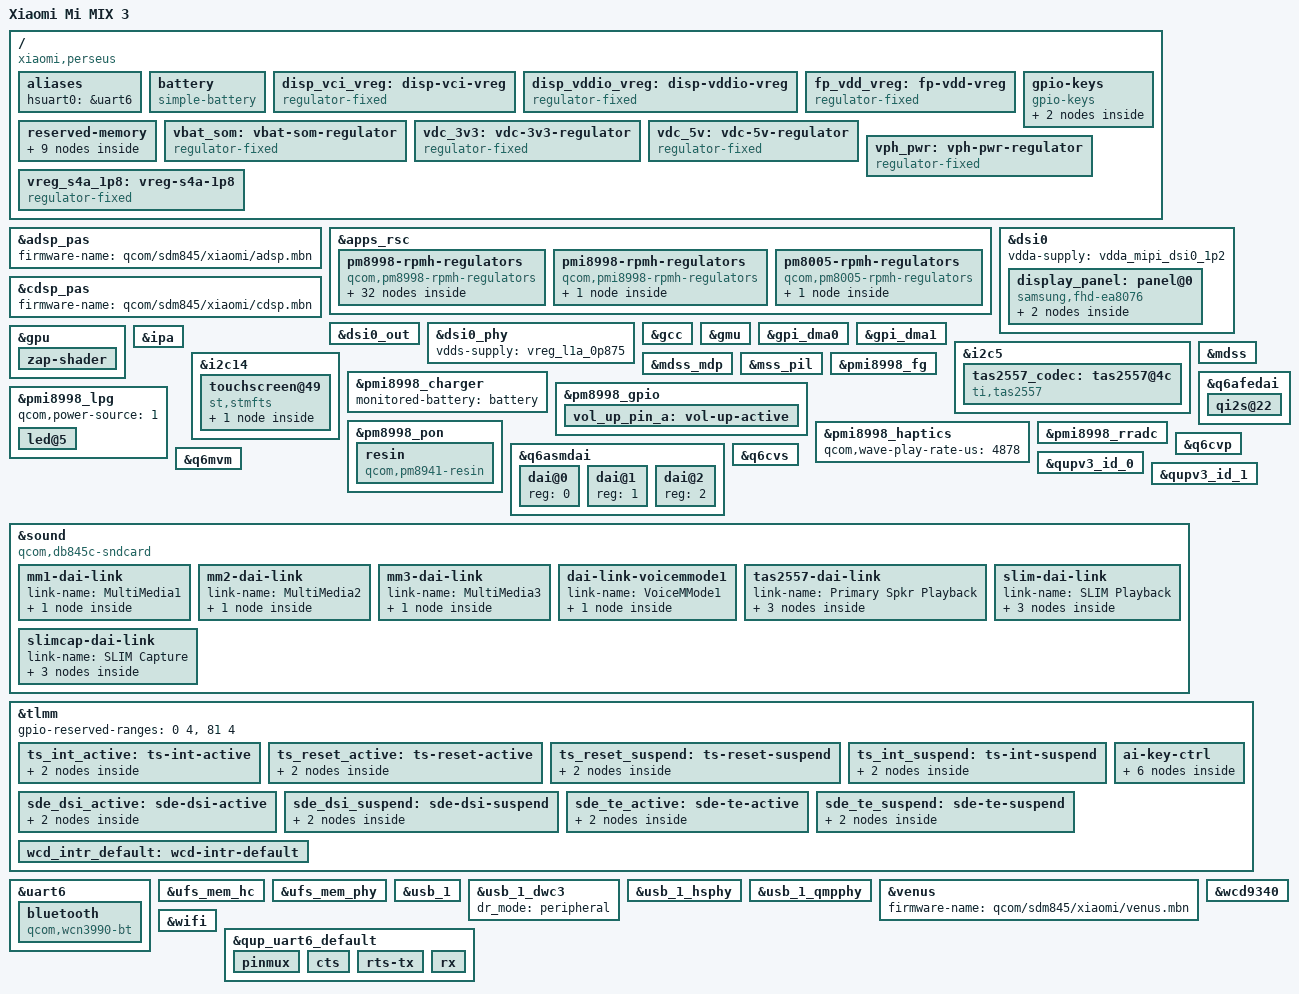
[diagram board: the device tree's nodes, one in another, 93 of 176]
// SPDX-License-Identifier: GPL-2.0
/*
 * Copyright (c) 2021, BigfootACA <bigfoot@classfun.cn>
 * Copyright (c) 2022, Pysen X <pysen@svartavillan.se>
 */

/dts-v1/;

#include <dt-bindings/gpio/gpio.h>
#include <dt-bindings/pinctrl/qcom,pmic-gpio.h>
#include <dt-bindings/regulator/qcom,rpmh-regulator.h>
#include <dt-bindings/sound/qcom,q6afe.h>
#include <dt-bindings/sound/qcom,q6asm.h>
#include <dt-bindings/sound/qcom,q6afe.h>
#include <dt-bindings/sound/qcom,q6asm.h>
#include <dt-bindings/sound/qcom,q6voice.h>
#include "sdm845.dtsi"
#include "pm8998.dtsi"
#include "pmi8998.dtsi"
#include "pm8005.dtsi"

/*
 * Delete following upstream (sdm845.dtsi) reserved
 * memory mappings which are different in this device.
 */
/delete-node/ &rmtfs_mem;
/delete-node/ &adsp_mem;
/delete-node/ &wlan_msa_mem;
/delete-node/ &mpss_region;
/delete-node/ &venus_mem;
/delete-node/ &cdsp_mem;
/delete-node/ &mba_region;
/delete-node/ &slpi_mem;
/delete-node/ &spss_mem;

/ {
	model = "Xiaomi Mi MIX 3";
	compatible = "xiaomi,perseus", "qcom,sdm845";

	/* required for bootloader to select correct board */
	qcom,board-id = <0x63 0x0>;
	qcom,msm-id = <0x141 0x20001>;
	aliases {
		hsuart0 = &uart6;	
	};

	battery: battery {
		compatible = "simple-battery";

		charge-full-design-microamp-hours = <3200000>;
		voltage-min-design-microvolt = <3700000>;
		voltage-max-design-microvolt = <4400000>;
	};

	disp_vci_vreg: disp-vci-vreg {
		compatible = "regulator-fixed";
		regulator-name = "disp_vci_vreg";
		start-delay-us = <4000>;
		regulator-always-on;
		regulator-boot-on;
		enable-active-high;
		gpio = <&tlmm 99 0>;
	};

	disp_vddio_vreg: disp-vddio-vreg {
		compatible = "regulator-fixed";
		regulator-name = "disp_vddio_vreg";
		startup-delay-us = <4000>;
		regulator-always-on;
		regulator-boot-on;
		enable-active-high;
		gpio = <&tlmm 79 0>;
	};

	fp_vdd_vreg: fp-vdd-vreg {
		compatible = "regulator-fixed";
		regulator-name = "fp_vdd_vreg";
		startup-delay-us = <4000>;
		regulator-always-on;
		enable-active-high;
		gpio = <&tlmm 50 0>;
	};

	gpio-keys {
		compatible = "gpio-keys";
		autorepeat;

		pinctrl-names = "default";
		pinctrl-0 = <&vol_up_pin_a &ai_key_active_default>;

		vol-up {
			label = "Volume Up";
			linux,code = <KEY_VOLUMEUP>;
			gpios = <&pm8998_gpio 6 GPIO_ACTIVE_LOW>;
		};

		ai-key {
			label = "AI Key";
			linux,code = <KEY_ASSISTANT>;
			gpios = <&tlmm 44 GPIO_ACTIVE_LOW>;
			// debounce-interval = <39>;
		};
	};

	/* Reserved memory changes from downstream */
	reserved-memory {
		adsp_mem: memory@8c500000 {
			reg = <0 0x8c500000 0 0x1e00000>;
			no-map;
		};

		wlan_msa_mem: memory@8e300000 {
			reg = <0 0x8e300000 0 0x100000>;
			no-map;
		};

		mpss_region: memory@8e400000 {
			reg = <0 0x8e400000 0 0x7800000>;
			no-map;
		};

		venus_mem: memory@95c00000 {
			reg = <0 0x95c00000 0 0x500000>;
			no-map;
		};

		cdsp_mem: memory@96100000 {
			reg = <0 0x96100000 0 0x800000>;
			no-map;
		};

		mba_region: memory@96900000 {
			reg = <0 0x96900000 0 0x200000>;
			no-map;
		};

		slpi_mem: memory@96b00000 {
			reg = <0 0x96b00000 0 0x1400000>;
			no-map;
		};

		spss_mem: memory@97f00000 {
			reg = <0 0x97f00000 0 0x100000>;
			no-map;
		};

		rmtfs_mem: memory@f6301000 {
			compatible = "qcom,rmtfs-mem";
			reg = <0 0xf6301000 0 0x200000>;
			no-map;

			qcom,client-id = <1>;
			qcom,vmid = <15>;
		};
	};

	vbat_som: vbat-som-regulator {
		compatible = "regulator-fixed";
		regulator-name = "VBAT_SOM";
		vin-supply = <&vph_pwr>;
		regulator-min-microvolt = <4200000>;
		regulator-max-microvolt = <4200000>;
		regulator-always-on;
	};

	vdc_3v3: vdc-3v3-regulator {
		compatible = "regulator-fixed";
		regulator-name = "VDC_3V3";
		vin-supply = <&vph_pwr>;
		regulator-min-microvolt = <3300000>;
		regulator-max-microvolt = <3300000>;
		regulator-always-on;
	};

	vdc_5v: vdc-5v-regulator {
		compatible = "regulator-fixed";
		regulator-name = "VDC_5V";
		vin-supply = <&vph_pwr>;
		regulator-min-microvolt = <500000>;
		regulator-max-microvolt = <500000>;
		regulator-always-on;
	};

	vph_pwr: vph-pwr-regulator {
		compatible = "regulator-fixed";
		regulator-name = "vph_pwr";
		regulator-min-microvolt = <3700000>;
		regulator-max-microvolt = <3700000>;
	};

	vreg_s4a_1p8: vreg-s4a-1p8 {
		compatible = "regulator-fixed";
		regulator-name = "vreg_s4a_1p8";

		regulator-min-microvolt = <1800000>;
		regulator-max-microvolt = <1800000>;
		regulator-always-on;
		regulator-boot-on;
		vin-supply = <&vph_pwr>;
	};
};

&adsp_pas {
	status = "okay";
	firmware-name = "qcom/sdm845/xiaomi/adsp.mbn";
};

&apps_rsc {
	pm8998-rpmh-regulators {
		compatible = "qcom,pm8998-rpmh-regulators";
		qcom,pmic-id = "a";
		vdd-s1-supply = <&vph_pwr>;
		vdd-s2-supply = <&vph_pwr>;
		vdd-s3-supply = <&vph_pwr>;
		vdd-s4-supply = <&vph_pwr>;
		vdd-s5-supply = <&vph_pwr>;
		vdd-s6-supply = <&vph_pwr>;
		vdd-s7-supply = <&vph_pwr>;
		vdd-s8-supply = <&vph_pwr>;
		vdd-s9-supply = <&vph_pwr>;
		vdd-s10-supply = <&vph_pwr>;
		vdd-s11-supply = <&vph_pwr>;
		vdd-s12-supply = <&vph_pwr>;
		vdd-s13-supply = <&vph_pwr>;
		vdd-l1-l27-supply = <&vreg_s7a_1p025>;
		vdd-l2-l8-l17-supply = <&vreg_s3a_1p35>;
		vdd-l3-l11-supply = <&vreg_s7a_1p025>;
		vdd-l4-l5-supply = <&vreg_s7a_1p025>;
		vdd-l6-supply = <&vph_pwr>;
		vdd-l7-l12-l14-l15-supply = <&vreg_s5a_2p04>;
		vdd-l9-supply = <&vreg_bob>;
		vdd-l10-l23-l25-supply = <&vreg_bob>;
		vdd-l13-l19-l21-supply = <&vreg_bob>;
		vdd-l16-l28-supply = <&vreg_bob>;
		vdd-l18-l22-supply = <&vreg_bob>;
		vdd-l20-l24-supply = <&vreg_bob>;
		vdd-l26-supply = <&vreg_s3a_1p35>;
		vin-lvs-1-2-supply = <&vreg_s4a_1p8>;

		vreg_s2a_1p1: smps2 {
			regulator-always-on;
			regulator-min-microvolt = <1100000>;
			regulator-max-microvolt = <1100000>;
		};

		vreg_s3a_1p35: smps3 {
			regulator-min-microvolt = <1352000>;
			regulator-max-microvolt = <1352000>;
		};

		vreg_s5a_2p04: smps5 {
			regulator-always-on;
			regulator-min-microvolt = <1904000>;
			regulator-max-microvolt = <2040000>;
		};

		vreg_s7a_1p025: smps7 {
			regulator-always-on;
			regulator-min-microvolt = <900000>;
			regulator-max-microvolt = <1028000>;
		};

		vdda_ufs1_core:
		vreg_l1a_0p875: ldo1 {
			regulator-min-microvolt = <880000>;
			regulator-max-microvolt = <880000>;
			regulator-initial-mode = <RPMH_REGULATOR_MODE_HPM>;
		};

		vreg_l2a_0p875: ldo2 {
			regulator-min-microvolt = <1200000>;
			regulator-max-microvolt = <1200000>;
			regulator-initial-mode = <RPMH_REGULATOR_MODE_HPM>;
			regulator-always-on;
		};

		reg_l3a_0p875: ldo3 {
			regulator-min-microvolt = <1000000>;
			regulator-max-microvolt = <1000000>;
			regulator-initial-mode = <RPMH_REGULATOR_MODE_HPM>;
		};

		vreg_l5a_0p8: ldo5 {
			regulator-min-microvolt = <800000>;
			regulator-max-microvolt = <800000>;
			regulator-initial-mode = <RPMH_REGULATOR_MODE_HPM>;
		};

		vreg_l6a_1p8: ldo6 {
			regulator-min-microvolt = <1856000>;
			regulator-max-microvolt = <1856000>;
			regulator-initial-mode = <RPMH_REGULATOR_MODE_HPM>;
		};

		vreg_l7a_1p8: ldo7 {
			regulator-min-microvolt = <1800000>;
			regulator-max-microvolt = <1800000>;
			regulator-initial-mode = <RPMH_REGULATOR_MODE_HPM>;
		};

		vreg_l8a_1p2: ldo8 {
			regulator-min-microvolt = <1200000>;
			regulator-max-microvolt = <1248000>;
			regulator-initial-mode = <RPMH_REGULATOR_MODE_HPM>;
		};

		vreg_l9a_2p95: ldo9 {
			regulator-min-microvolt = <1704000>;
			regulator-max-microvolt = <2928000>;
			regulator-initial-mode = <RPMH_REGULATOR_MODE_HPM>;
		};

		vreg_l10a_2p95: ldo10 {
			regulator-min-microvolt = <1704000>;
			regulator-max-microvolt = <2928000>;
			regulator-initial-mode = <RPMH_REGULATOR_MODE_HPM>;
		};

		vreg_l11a_1p05: ldo11 {
			regulator-min-microvolt = <1000000>;
			regulator-max-microvolt = <1048000>;
			regulator-initial-mode = <RPMH_REGULATOR_MODE_HPM>;
		};

		vreg_l12a_1p8: ldo12 {
			regulator-min-microvolt = <1800000>;
			regulator-max-microvolt = <1800000>;
			regulator-initial-mode = <RPMH_REGULATOR_MODE_HPM>;
		};

		vreg_l13a_2p95: ldo13 {
			regulator-min-microvolt = <1800000>;
			regulator-max-microvolt = <2960000>;
			regulator-initial-mode = <RPMH_REGULATOR_MODE_HPM>;
		};

		vreg_l14a_1p8: ldo14 {
			regulator-min-microvolt = <1800000>;
			regulator-max-microvolt = <1800000>;
			regulator-always-on;
			regulator-boot-on;
			regulator-initial-mode = <RPMH_REGULATOR_MODE_HPM>;
		};

		vreg_l15a_1p8: ldo15 {
			regulator-min-microvolt = <1800000>;
			regulator-max-microvolt = <1800000>;
			regulator-initial-mode = <RPMH_REGULATOR_MODE_HPM>;
		};

		vreg_l16a_2p7: ldo16 {
			regulator-min-microvolt = <2704000>;
			regulator-max-microvolt = <2704000>;
			regulator-initial-mode = <RPMH_REGULATOR_MODE_HPM>;
		};

		vreg_l17a_1p3: ldo17 {
			regulator-always-on;
			regulator-min-microvolt = <1304000>;
			regulator-max-microvolt = <1304000>;
			regulator-initial-mode = <RPMH_REGULATOR_MODE_HPM>;
		};

		vreg_l18a_2p9: ldo18 {
			regulator-min-microvolt = <2704000>;
			regulator-max-microvolt = <2960000>;
			regulator-initial-mode = <RPMH_REGULATOR_MODE_HPM>;
		};

		vreg_l19a_3p1: ldo19 {
			regulator-min-microvolt = <2856000>;
			regulator-max-microvolt = <3104000>;
			regulator-initial-mode = <RPMH_REGULATOR_MODE_HPM>;
		};

		vreg_l20a_2p95: ldo20 {
			regulator-min-microvolt = <2704000>;
			regulator-max-microvolt = <2960000>;
			regulator-initial-mode = <RPMH_REGULATOR_MODE_HPM>;
		};

		vreg_l21a_2p95: ldo21 {
			regulator-min-microvolt = <2704000>;
			regulator-max-microvolt = <2960000>;
			regulator-initial-mode = <RPMH_REGULATOR_MODE_HPM>;
		};

		vreg_l22a_3p3: ldo22 {
			regulator-min-microvolt = <2864000>;
			regulator-max-microvolt = <3312000>;
			regulator-initial-mode = <RPMH_REGULATOR_MODE_HPM>;
		};

		vreg_l23a_3p3: ldo23 {
			regulator-min-microvolt = <3000000>;
			regulator-max-microvolt = <3312000>;
			regulator-initial-mode = <RPMH_REGULATOR_MODE_HPM>;
		};

		vreg_l24a_3p075: ldo24 {
			regulator-min-microvolt = <3088000>;
			regulator-max-microvolt = <3088000>;
			regulator-initial-mode = <RPMH_REGULATOR_MODE_HPM>;
		};

		vreg_l25a_3p3: ldo25 {
			regulator-always-on;
			regulator-min-microvolt = <3000000>;
			regulator-max-microvolt = <3312000>;
			regulator-initial-mode = <RPMH_REGULATOR_MODE_HPM>;
		};

		vdda_mipi_dsi0_1p2:
		vdda_ufs1_1p2:
		vreg_l26a_1p2: ldo26 {
			regulator-min-microvolt = <1200000>;
			regulator-max-microvolt = <1200000>;
			regulator-initial-mode = <RPMH_REGULATOR_MODE_HPM>;
			regulator-boot-on;
		};

		vreg_l28a_3p0: ldo28 {
			regulator-min-microvolt = <2856000>;
			regulator-max-microvolt = <3008000>;
			regulator-initial-mode = <RPMH_REGULATOR_MODE_HPM>;
			regulator-always-on;
		};

		vreg_lvs1a_1p8: lvs1 {
			regulator-min-microvolt = <1800000>;
			regulator-max-microvolt = <1800000>;
			regulator-always-on;
		};

		vreg_lvs2a_1p8: lvs2 {
			regulator-min-microvolt = <1800000>;
			regulator-max-microvolt = <1800000>;
			regulator-always-on;
		};
	};

	pmi8998-rpmh-regulators {
		compatible = "qcom,pmi8998-rpmh-regulators";
		qcom,pmic-id = "b";
		vdd-bob-supply = <&vph_pwr>;
		vreg_bob: bob {
			regulator-min-microvolt = <3312000>;
			regulator-max-microvolt = <3600000>;
			regulator-initial-mode = <RPMH_REGULATOR_MODE_AUTO>;
			regulator-allow-bypass;
		};
	};

	pm8005-rpmh-regulators {
		compatible = "qcom,pm8005-rpmh-regulators";
		qcom,pmic-id = "c";
		vdd-s1-supply = <&vph_pwr>;
		vdd-s2-supply = <&vph_pwr>;
		vdd-s3-supply = <&vph_pwr>;
		vdd-s4-supply = <&vph_pwr>;
		vreg_smp3c_0p6: smps3 {
			regulator-min-microvolt = <600000>;
			regulator-max-microvolt = <600000>;
			regulator-always-on;
		};
	};
};

&cdsp_pas {
	status = "okay";
	firmware-name = "qcom/sdm845/xiaomi/cdsp.mbn";
};

&dsi0 {
	status = "okay";
	vdda-supply = <&vdda_mipi_dsi0_1p2>;

	#address-cells = <1>;
	#size-cells = <0>;

	display_panel: panel@0 {
		compatible = "samsung,fhd-ea8076";
		#address-cells = <1>;
		#size-cells = <0>;
		reg = <0>;
		vddio-supply = <&vreg_l14a_1p8>;
		reset-gpios = <&tlmm 6 GPIO_ACTIVE_LOW>;
		pinctrl-names = "default";
		pinctrl-0 = <&sde_dsi_active &sde_te_active>;
		port {
			panel_in: endpoint {
				remote-endpoint = <&dsi0_out>;
			};
		};
	};
};

&dsi0_out {
	remote-endpoint = <&panel_in>;
	data-lanes = <0 1 2 3>;
};

&dsi0_phy {
	status = "okay";
	vdds-supply = <&vreg_l1a_0p875>;
};

&gcc {
	protected-clocks = <GCC_QSPI_CORE_CLK>,
			   <GCC_QSPI_CORE_CLK_SRC>,
			   <GCC_QSPI_CNOC_PERIPH_AHB_CLK>,
			   <GCC_LPASS_Q6_AXI_CLK>,
			   <GCC_LPASS_SWAY_CLK>;
};

&gmu {
	status = "okay";
};

&gpi_dma0 {
	status = "okay";
};

&gpi_dma1 {
	status = "okay";
};

&gpu {
	status = "okay";

	zap-shader {
		memory-region = <&gpu_mem>;
		firmware-name = "qcom/sdm845/xiaomi/a630_zap.mbn";
	};
};

&ipa {
	status = "okay";
	memory-region = <&ipa_fw_mem>;
	firmware-name = "qcom/sdm845/xiaomi/ipa_fws.mbn";
};

&i2c5 {
	#dma-cells = <3>;
	status = "okay";

	clock-frequency = <400000>;
	dmas = <&gpi_dma0 0 5 QCOM_GPI_I2C>,
		   <&gpi_dma0 1 5 QCOM_GPI_I2C>;
	dma-names = "tx", "rx";

	tas2557_codec: tas2557@4c{
		#sound-dai-cells = <1>;
		compatible = "ti,tas2557";
		reg = <0x4c>;
		ti,cdc-reset-gpio = <&tlmm 69 0>;
		ti,irq-gpio = <&tlmm 30 0>;
		ti,i2s-bits = <16>;
		ti,bypass-tmax = <0>;
	};
};

&i2c14 {
	#dma-cells = <3>;
	status = "okay";

	clock-frequency = <400000>;

	dmas =  <&gpi_dma1 0 6 QCOM_GPI_I2C>,
		   <&gpi_dma1 1 6 QCOM_GPI_I2C>;
	dma-names = "tx", "rx";

	touchscreen@49 {
		compatible = "st,stmfts";
		reg = <0x49>;
		interrupt-parent = <&tlmm>;
		interrupts = <31 0x2008>;
		pinctrl-names = "pmx_ts_active", "pmx_ts_suspend";
		pinctrl-0 = <&ts_int_active &ts_reset_active>;
		pinctrl-1 = <&ts_int_suspend &ts_reset_suspend>;
		vdd-supply = <&disp_vddio_vreg>;
		avdd-supply = <&vreg_l28a_3p0>;
		fts,pwr-reg-name = "avdd";
		fts,bus-reg-name = "vdd";
		fts,irq-gpio = <&tlmm 31 0x2008>;
		fts,irq-gpio-name = "fts_irq";
		fts,reset-gpio-enable;
		fts,reset-gpio = <&tlmm 32 0x00>;
		fts,x-max = <1079>;
		fts,y-max = <2339>;
		fts,reset-gpio-name = "fts_rst";
		fts,irq-flags = <0x2008>;
		fts,key-num = <2>;
		fts,key-codes = <158 139>;
		fts,config-array-size = <1>;
		fts,default-fw-name = "st_fts_e5.ftb";
		fts,cfg_0 {
			fts,tp-vendor = <0x52>;
			fts,fw-name = "st_fts_e5.ftb";
			fts,limit-name = "stm_fts_production_limits.csv";
		};
	};
};

&mdss {
	status = "okay";
};

&mdss_mdp {
	status = "okay";
};

&mss_pil {
	status = "okay";
	firmware-name = "qcom/sdm845/xiaomi/mba.mbn", "qcom/sdm845/xiaomi/modem.mbn";
};

&pmi8998_charger {
	status = "okay";
	monitored-battery = <&battery>;
};

&pmi8998_fg {
	status = "okay";

	power-supplies = <&pmi8998_charger>;
	monitored-battery = <&battery>;
};

&pm8998_gpio {
	vol_up_pin_a: vol-up-active {
		pins = "gpio6";
		function = "normal";
		input-enable;
		bias-pull-up;
		qcom,drive-strength = <PMIC_GPIO_STRENGTH_NO>;
	};
};

&pmi8998_haptics {
	status = "okay";
	qcom,wave-play-rate-us = <4878>;
};

&pmi8998_lpg {
	status = "okay";
	qcom,power-source = <1>;
	led@5 {
		reg = <5>;
		label = "white";
	};
};

&pm8998_pon {
	resin {
		compatible = "qcom,pm8941-resin";
		interrupts = <0x0 0x8 1 IRQ_TYPE_EDGE_BOTH>;
		debounce = <15625>;
		bias-pull-up;
		linux,code = <KEY_VOLUMEDOWN>;
	};
};

&pmi8998_rradc {
	status = "okay";
};

&q6afedai {
	qi2s@22 {
		reg = <22>;
		qcom,sd-lines = <0 1 2 3>;
	};
};

&q6asmdai {
	dai@0 {
		reg = <0>;
	};

	dai@1 {
		reg = <1>;
	};

	dai@2 {
		reg = <2>;
	};
};

&q6cvp {
	status = "okay";
};

&q6cvs {
	status = "okay";
};

&q6mvm {
	status = "okay";
};

&qupv3_id_0 {
	status = "okay";
};

&qupv3_id_1 {
	status = "okay";
};

&sound {
	compatible = "qcom,db845c-sndcard";
	pinctrl-0 = <&quat_mi2s_active &quat_mi2s_sd0_active>;
	pinctrl-names = "default";
	model = "Xiaomi Mi MIX 3";
	audio-routing =
		"RX_BIAS", "MCLK",
		"AMIC1", "MIC BIAS1",
		"AMIC2", "MIC BIAS2",
		"AMIC3", "MIC BIAS3";

	mm1-dai-link {
		link-name = "MultiMedia1";
		cpu {
			sound-dai = <&q6asmdai MSM_FRONTEND_DAI_MULTIMEDIA1>;
		};
	};

	mm2-dai-link {
		link-name = "MultiMedia2";
		cpu {
			sound-dai = <&q6asmdai MSM_FRONTEND_DAI_MULTIMEDIA2>;
		};
	};

	mm3-dai-link {
		link-name = "MultiMedia3";
		cpu {
			sound-dai = <&q6asmdai MSM_FRONTEND_DAI_MULTIMEDIA3>;
		};
	};

	dai-link-voicemmode1 {
		link-name = "VoiceMMode1";
		cpu {
			sound-dai = <&q6voicedai VOICEMMODE1>;
		};
	};

	tas2557-dai-link {
		link-name = "Primary Spkr Playback";
		cpu {
			sound-dai = <&q6afedai QUATERNARY_MI2S_RX>;
		};

		platform {
			sound-dai = <&q6routing>;
		};

		codec {
			sound-dai = <&tas2557_codec 0>;
		};
	};

	slim-dai-link {
		link-name = "SLIM Playback";
		cpu {
			sound-dai = <&q6afedai SLIMBUS_0_RX>;
		};

		platform {
			sound-dai = <&q6routing>;
		};

		codec {
			sound-dai = <&wcd9340 0>;
		};
	};

	slimcap-dai-link {
		link-name = "SLIM Capture";
		cpu {
			sound-dai = <&q6afedai SLIMBUS_0_TX>;
		};

		platform {
			sound-dai = <&q6routing>;
		};

		codec {
			sound-dai = <&wcd9340 1>;
		};
	};
};

&tlmm {
	gpio-reserved-ranges = <0 4>, <81 4>;

	ts_int_active: ts-int-active {
		mux {
			pins = "gpio31";
			function = "gpio";
		};

		config {
			pins = "gpio31";
			drive-strength = <16>;
			bias-pull-down;
			input-enable;
		};
	};

	ts_reset_active: ts-reset-active {
		mux {
			pins = "gpio32";
			function = "gpio";
		};

		config {
			pins = "gpio32";
			drive-strength = <16>;
			output-high;
		};
	};

	ts_reset_suspend: ts-reset-suspend {
		mux {
			pins = "gpio32";
			function = "gpio";
		};

		config {
			pins = "gpio32";
			drive-strength = <2>;
			bias-disable;
			output-low;
		};
	};

	ts_int_suspend: ts-int-suspend {
		mux {
			pins = "gpio31";
			function = "gpio";
		};

		config {
			pins = "gpio31";
			drive-strength = <2>;
			bias-pull-down;
			input-enable;
		};
	};

	sde_dsi_active: sde-dsi-active {
		mux {
			pins = "gpio6", "gpio52";
			function = "gpio";
		};

		config {
			pins = "gpio6", "gpio52";
			drive-strength = <8>;   /* 8 mA */
			bias-disable = <0>;   /* no pull */
		};
	};

	sde_dsi_suspend: sde-dsi-suspend {
		mux {
			pins = "gpio6", "gpio52";
			function = "gpio";
		};

		config {
			pins = "gpio6", "gpio52";
			drive-strength = <2>;   /* 2 mA */
			bias-pull-down; /* PULL DOWN */
		};
	};

	sde_te_active: sde-te-active {
		mux {
			pins = "gpio10";
			function = "mdp_vsync";
		};

		config {
			pins = "gpio10";
			drive-strength = <2>;   /* 2 mA */
			bias-pull-down; /* PULL DOWN */
		};
	};

	sde_te_suspend: sde-te-suspend {
		mux {
			pins = "gpio10";
			function = "mdp_vsync";
		};

		config {
			pins = "gpio10";
			drive-strength = <2>;   /* 2 mA */
			bias-pull-down; /* PULL DOWN */
		};
	};

	ai-key-ctrl {
		ai_key_active_default: ai-key-active {
			mux {
				pins = "gpio44";
				function = "gpio";
			};
			config {
				pins = "gpio44";
				drive-strength = <2>;
				bias-pull-up;
				input-enable;
			};
		};

		ai_key_idle_default: ai-key-idle {
			mux {
				pins = "gpio44";
				function = "gpio";
			};
			config {
				pins = "gpio44";
				drive-strength = <2>;
				bias-pull-up;
				input-enable;
			};
		};
	};

	wcd_intr_default: wcd-intr-default {
		pins = <54>;
		function = "gpio";
		input-enable;
		bias-pull-down;
		drive-strength = <2>;
	};
};

&uart6 {
	status = "okay";

	bluetooth {
		compatible = "qcom,wcn3990-bt";

		vddio-supply = <&vreg_s4a_1p8>;
		vddxo-supply = <&vreg_l7a_1p8>;
		vddrf-supply = <&vreg_l17a_1p3>;
		vddch0-supply = <&vreg_l25a_3p3>;
		max-speed = <3200000>;
	};
};

&ufs_mem_hc {
	status = "okay";

	reset-gpios = <&tlmm 150 GPIO_ACTIVE_LOW>;

	vcc-supply = <&vreg_l20a_2p95>;
	vcc-max-microamp = <800000>;
};

&ufs_mem_phy {
	status = "okay";

	vdda-phy-supply = <&vdda_ufs1_core>;
	vdda-pll-supply = <&vdda_ufs1_1p2>;
};

&usb_1 {
	status = "okay";
};

&usb_1_dwc3 {
	dr_mode = "peripheral";
};

&usb_1_hsphy {
	status = "okay";

	vdd-supply = <&vreg_l1a_0p875>;
	vdda-pll-supply = <&vreg_l12a_1p8>;
	vdda-phy-dpdm-supply = <&vreg_l24a_3p075>;

	qcom,imp-res-offset-value = <8>;
	qcom,hstx-trim-value = <QUSB2_V2_HSTX_TRIM_21_6_MA>;
	qcom,preemphasis-level = <QUSB2_V2_PREEMPHASIS_5_PERCENT>;
	qcom,preemphasis-width = <QUSB2_V2_PREEMPHASIS_WIDTH_HALF_BIT>;
};

&usb_1_qmpphy {
	status = "okay";

	vdda-phy-supply = <&vreg_l26a_1p2>;
	vdda-pll-supply = <&vreg_l1a_0p875>;
};

&venus {
	status = "okay";
	firmware-name = "qcom/sdm845/xiaomi/venus.mbn";
};

&wcd9340{
	pinctrl-0 = <&wcd_intr_default>;
	pinctrl-names = "default";
	clock-names = "extclk";
	clocks = <&rpmhcc RPMH_LN_BB_CLK2>;
	reset-gpios = <&tlmm 64 0>;
	vdd-buck-supply = <&vreg_s4a_1p8>;
	vdd-buck-sido-supply = <&vreg_s4a_1p8>;
	vdd-tx-supply = <&vreg_s4a_1p8>;
	vdd-rx-supply = <&vreg_s4a_1p8>;
	vdd-io-supply = <&vreg_s4a_1p8>;
	qcom,micbias1-microvolt = <2700000>;
	qcom,micbias2-microvolt = <1800000>;
	qcom,micbias3-microvolt = <2700000>;
	qcom,micbias4-microvolt = <2700000>;
};

&wifi {
	status = "okay";

	vdd-0.8-cx-mx-supply = <&vreg_l5a_0p8>;
	vdd-1.8-xo-supply = <&vreg_l7a_1p8>;
	vdd-1.3-rfa-supply = <&vreg_l17a_1p3>;
	vdd-3.3-ch0-supply = <&vreg_l25a_3p3>;
	vdd-3.3-ch1-supply = <&vreg_l23a_3p3>;

	qcom,snoc-host-cap-skip-quirk;
};

/* PINCTRL - additions to nodes defined in sdm845.dtsi */

&qup_uart6_default {
	pinmux {
		pins = "gpio45", "gpio46", "gpio47", "gpio48";
		function = "qup6";
	};

	cts {
		pins = "gpio45";
		bias-disable;
	};

	rts-tx {
		pins = "gpio46", "gpio47";
		drive-strength = <2>;
		bias-disable;
	};

	rx {
		pins = "gpio48";
		bias-pull-up;
	};
};
